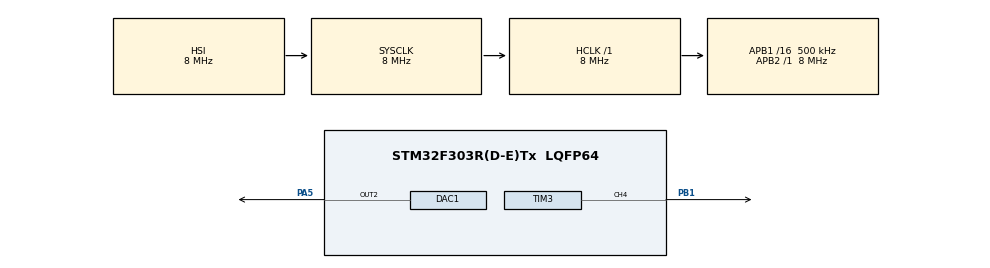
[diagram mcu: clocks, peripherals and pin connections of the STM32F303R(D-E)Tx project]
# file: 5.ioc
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DAC1.DAC_Trigger2=DAC_TRIGGER_T3_TRGO
Dma.DAC1_CH2.0.Direction=DMA_MEMORY_TO_PERIPH
Dma.DAC1_CH2.0.Instance=DMA1_Channel4
Dma.DAC1_CH2.0.MemDataAlignment=DMA_MDATAALIGN_HALFWORD
Dma.DAC1_CH2.0.MemInc=DMA_MINC_ENABLE
Dma.DAC1_CH2.0.Mode=DMA_CIRCULAR
Dma.DAC1_CH2.0.PeriphDataAlignment=DMA_PDATAALIGN_HALFWORD
Dma.DAC1_CH2.0.PeriphInc=DMA_PINC_DISABLE
Dma.DAC1_CH2.0.Priority=DMA_PRIORITY_LOW
Dma.Request0=DAC1_CH2
Mcu.Family=STM32F3
Mcu.Name=STM32F303R(D-E)Tx
Mcu.Package=LQFP64
NVIC.DMA1_Channel4_IRQn=true\:0\:0\:false\:false\:true\:false
NVIC.PriorityGroup=NVIC_PRIORITYGROUP_4
PA5.Signal=COMP_DAC12_group
PB1.Signal=S_TIM3_CH4
PF0-OSC_IN.Mode=HSE-External-Oscillator
PF0-OSC_IN.Signal=RCC_OSC_IN
PF1-OSC_OUT.Mode=HSE-External-Oscillator
PF1-OSC_OUT.Signal=RCC_OSC_OUT
ProjectManager.HeapSize=0x200
ProjectManager.StackSize=0x400
ProjectManager.TargetToolchain=TrueSTUDIO
RCC.AHBFreq_Value=8000000
RCC.APB1CLKDivider=RCC_HCLK_DIV16
RCC.APB1Freq_Value=500000
RCC.APB1TimFreq_Value=1000000
RCC.APB2Freq_Value=8000000
RCC.CortexFreq_Value=8000000
RCC.HSE_VALUE=8000000
RCC.HSI_VALUE=8000000
RCC.LSE_VALUE=32768
RCC.SYSCLKFreq_VALUE=8000000
RCC.USBFreq_Value=16000000
SH.COMP_DAC12_group.0=DAC1_OUT2,Enable_DAC_OUT2
SH.S_TIM3_CH4.0=TIM3_CH4,PWM Generation4 CH4
TIM3.AutoReloadPreload=TIM_AUTORELOAD_PRELOAD_DISABLE
TIM3.Channel-PWM\ Generation4\ CH4=TIM_CHANNEL_4
TIM3.Period=1
TIM3.Prescaler=9999
TIM3.Pulse-PWM\ Generation4\ CH4=1
TIM3.TIM_MasterOutputTrigger=TIM_TRGO_OC4REF
board=5

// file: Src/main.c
/**
  ******************************************************************************
  * @file           : main.c
  * @brief          : Main program body
  ******************************************************************************
  ** This notice applies to any and all portions of this file
  * that are not between comment pairs USER CODE BEGIN and
  * USER CODE END. Other portions of this file, whether
  * inserted by the user or by software development tools
  * are owned by their respective copyright owners.
  *
  * COPYRIGHT(c) 2018 STMicroelectronics
  *
  * Redistribution and use in source and binary forms, with or without modification,
  * are permitted provided that the following conditions are met:
  *   1. Redistributions of source code must retain the above copyright notice,
  *      this list of conditions and the following disclaimer.
  *   2. Redistributions in binary form must reproduce the above copyright notice,
  *      this list of conditions and the following disclaimer in the documentation
  *      and/or other materials provided with the distribution.
  *   3. Neither the name of STMicroelectronics nor the names of its contributors
  *      may be used to endorse or promote products derived from this software
  *      without specific prior written permission.
  *
  * THIS SOFTWARE IS PROVIDED BY THE COPYRIGHT HOLDERS AND CONTRIBUTORS "AS IS"
  * AND ANY EXPRESS OR IMPLIED WARRANTIES, INCLUDING, BUT NOT LIMITED TO, THE
  * IMPLIED WARRANTIES OF MERCHANTABILITY AND FITNESS FOR A PARTICULAR PURPOSE ARE
  * DISCLAIMED. IN NO EVENT SHALL THE COPYRIGHT HOLDER OR CONTRIBUTORS BE LIABLE
  * FOR ANY DIRECT, INDIRECT, INCIDENTAL, SPECIAL, EXEMPLARY, OR CONSEQUENTIAL
  * DAMAGES (INCLUDING, BUT NOT LIMITED TO, PROCUREMENT OF SUBSTITUTE GOODS OR
  * SERVICES; LOSS OF USE, DATA, OR PROFITS; OR BUSINESS INTERRUPTION) HOWEVER
  * CAUSED AND ON ANY THEORY OF LIABILITY, WHETHER IN CONTRACT, STRICT LIABILITY,
  * OR TORT (INCLUDING NEGLIGENCE OR OTHERWISE) ARISING IN ANY WAY OUT OF THE USE
  * OF THIS SOFTWARE, EVEN IF ADVISED OF THE POSSIBILITY OF SUCH DAMAGE.
  *
  ******************************************************************************
  */
#include "main.h"
#include "stm32f3xx_hal.h"

DAC_HandleTypeDef hdac1;
DMA_HandleTypeDef hdma_dac1_ch2;

TIM_HandleTypeDef htim3;

/* USER CODE BEGIN PV */
/* Private variables ---------------------------------------------------------*/
uint16_t sine[100]={2048,2112,2176,2240,2303,2364,2425,2484,2541,2597,2650,2701,2749,2794,2837,2876,2913,2945,2975,3000,3022,3040,3054,3064,3070,3072,3070,3064,3054,3040,3022,3000,2975,2945,2913,2876,2837,
2794,2749,2701,2650,2597,2541,2484,2425,2364,2303,2240,2176,2112,2048,1984,1920,1856,1793,1732,1671,1612,1555,1499,1446,1395,1347,1302,1259,1220,1183,1151,1121,1096,1074,1056,1042,1032,1026,1024,1026,1032,1042,1056,1074,1096,1121,1151,1183,1220,1259,1302,1347,1395,1446,1499,1555,1612,1671,1732,1793,1856,1920,1984};
/* USER CODE END PV */

void SystemClock_Config(void);
static void MX_GPIO_Init(void);
static void MX_DMA_Init(void);
static void MX_TIM3_Init(void);
static void MX_DAC1_Init(void);

void HAL_TIM_MspPostInit(TIM_HandleTypeDef *htim);

/* USER CODE BEGIN PFP */
/* Private function prototypes -----------------------------------------------*/

/* USER CODE END PFP */

int main(void)
{

  /* MCU Configuration----------------------------------------------------------*/

  /* Reset of all peripherals, Initializes the Flash interface and the Systick. */
  HAL_Init();

  /* Configure the system clock */
  SystemClock_Config();

  /* Initialize all configured peripherals */
  MX_GPIO_Init();
  MX_DMA_Init();
  MX_TIM3_Init();
  MX_DAC1_Init();
  /* USER CODE BEGIN 2 */
  HAL_DAC_Start_DMA(&hdac1,DAC_CHANNEL_2,sine,100,DAC_ALIGN_12B_R);
  HAL_TIM_PWM_Start(&htim3,TIM_CHANNEL_4);
  /* USER CODE END 2 */

  /* Infinite loop */
  while (1)
  {

  }

}

void SystemClock_Config(void)
{

  RCC_OscInitTypeDef RCC_OscInitStruct;
  RCC_ClkInitTypeDef RCC_ClkInitStruct;
  RCC_PeriphCLKInitTypeDef PeriphClkInit;

    /**Initializes the CPU, AHB and APB busses clocks
    */
  RCC_OscInitStruct.OscillatorType = RCC_OSCILLATORTYPE_HSI;
  RCC_OscInitStruct.HSIState = RCC_HSI_ON;
  RCC_OscInitStruct.HSICalibrationValue = 16;
  RCC_OscInitStruct.PLL.PLLState = RCC_PLL_NONE;
  if (HAL_RCC_OscConfig(&RCC_OscInitStruct) != HAL_OK)
  {
    _Error_Handler(__FILE__, __LINE__);
  }

    /**Initializes the CPU, AHB and APB busses clocks
    */
  RCC_ClkInitStruct.ClockType = RCC_CLOCKTYPE_HCLK|RCC_CLOCKTYPE_SYSCLK
                              |RCC_CLOCKTYPE_PCLK1|RCC_CLOCKTYPE_PCLK2;
  RCC_ClkInitStruct.SYSCLKSource = RCC_SYSCLKSOURCE_HSI;
  RCC_ClkInitStruct.AHBCLKDivider = RCC_SYSCLK_DIV1;
  RCC_ClkInitStruct.APB1CLKDivider = RCC_HCLK_DIV16;
  RCC_ClkInitStruct.APB2CLKDivider = RCC_HCLK_DIV1;

  if (HAL_RCC_ClockConfig(&RCC_ClkInitStruct, FLASH_LATENCY_0) != HAL_OK)
  {
    _Error_Handler(__FILE__, __LINE__);
  }

  PeriphClkInit.PeriphClockSelection = RCC_PERIPHCLK_TIM34;
  PeriphClkInit.Tim34ClockSelection = RCC_TIM34CLK_HCLK;
  if (HAL_RCCEx_PeriphCLKConfig(&PeriphClkInit) != HAL_OK)
  {
    _Error_Handler(__FILE__, __LINE__);
  }

    /**Configure the Systick interrupt time
    */
  HAL_SYSTICK_Config(HAL_RCC_GetHCLKFreq()/1000);

    /**Configure the Systick
    */
  HAL_SYSTICK_CLKSourceConfig(SYSTICK_CLKSOURCE_HCLK);

  /* SysTick_IRQn interrupt configuration */
  HAL_NVIC_SetPriority(SysTick_IRQn, 0, 0);
}

/* DAC1 init function */
static void MX_DAC1_Init(void)
{

  DAC_ChannelConfTypeDef sConfig;

    /**DAC Initialization
    */
  hdac1.Instance = DAC1;
  if (HAL_DAC_Init(&hdac1) != HAL_OK)
  {
    _Error_Handler(__FILE__, __LINE__);
  }

    /**DAC channel OUT2 config
    */
  sConfig.DAC_Trigger = DAC_TRIGGER_T3_TRGO;
  sConfig.DAC_OutputBuffer = DAC_OUTPUTBUFFER_ENABLE;
  if (HAL_DAC_ConfigChannel(&hdac1, &sConfig, DAC_CHANNEL_2) != HAL_OK)
  {
    _Error_Handler(__FILE__, __LINE__);
  }

  __HAL_REMAPTRIGGER_ENABLE(HAL_REMAPTRIGGER_DAC1_TRIG);

}

/* TIM3 init function */
static void MX_TIM3_Init(void)
{

  TIM_MasterConfigTypeDef sMasterConfig;
  TIM_OC_InitTypeDef sConfigOC;

  htim3.Instance = TIM3;
  htim3.Init.Prescaler = 9999;
  htim3.Init.CounterMode = TIM_COUNTERMODE_UP;
  htim3.Init.Period = 1;
  htim3.Init.ClockDivision = TIM_CLOCKDIVISION_DIV1;
  htim3.Init.AutoReloadPreload = TIM_AUTORELOAD_PRELOAD_DISABLE;
  if (HAL_TIM_PWM_Init(&htim3) != HAL_OK)
  {
    _Error_Handler(__FILE__, __LINE__);
  }

  sMasterConfig.MasterOutputTrigger = TIM_TRGO_OC4REF;
  sMasterConfig.MasterSlaveMode = TIM_MASTERSLAVEMODE_DISABLE;
  if (HAL_TIMEx_MasterConfigSynchronization(&htim3, &sMasterConfig) != HAL_OK)
  {
    _Error_Handler(__FILE__, __LINE__);
  }

  sConfigOC.OCMode = TIM_OCMODE_PWM1;
  sConfigOC.Pulse = 1;
  sConfigOC.OCPolarity = TIM_OCPOLARITY_HIGH;
  sConfigOC.OCFastMode = TIM_OCFAST_DISABLE;
  if (HAL_TIM_PWM_ConfigChannel(&htim3, &sConfigOC, TIM_CHANNEL_4) != HAL_OK)
  {
    _Error_Handler(__FILE__, __LINE__);
  }

  HAL_TIM_MspPostInit(&htim3);

}

static void MX_DMA_Init(void)
{
  /* DMA controller clock enable */
  __HAL_RCC_DMA1_CLK_ENABLE();

  /* DMA interrupt init */
  /* DMA1_Channel4_IRQn interrupt configuration */
  HAL_NVIC_SetPriority(DMA1_Channel4_IRQn, 0, 0);
  HAL_NVIC_EnableIRQ(DMA1_Channel4_IRQn);

}

/** Configure pins as
        * Analog
        * Input
        * Output
        * EVENT_OUT
        * EXTI
*/
static void MX_GPIO_Init(void)
{

  /* GPIO Ports Clock Enable */
  __HAL_RCC_GPIOF_CLK_ENABLE();
  __HAL_RCC_GPIOA_CLK_ENABLE();
  __HAL_RCC_GPIOB_CLK_ENABLE();

}

void _Error_Handler(char *file, int line)
{
  while(1)
  {
  }
}

/************************ (C) COPYRIGHT STMicroelectronics *****END OF FILE****/
